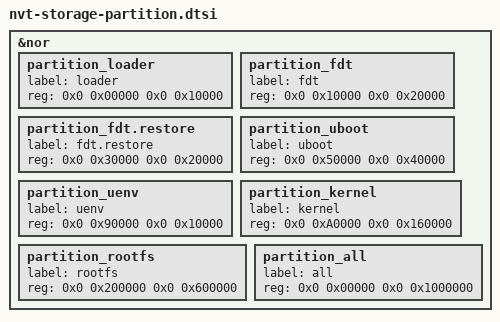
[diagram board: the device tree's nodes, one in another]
/*
 * Novatek Ltd. NA51055 BSP part of dts
 *
 * Cortex-A9
 *
 */

&nor {
	partition_loader {      label = "loader";       reg = <0x0 0x00000   0x0 0x10000>; }; /* Fixed */
	partition_fdt {	        label = "fdt";	        reg = <0x0 0x10000   0x0 0x20000>; }; /* Fixed */
	partition_fdt.restore {	label = "fdt.restore";	reg = <0x0 0x30000   0x0 0x20000>; }; /* Fixed */
	partition_uboot {       label = "uboot";        reg = <0x0 0x50000   0x0 0x40000>; };
	partition_uenv {        label = "uenv";         reg = <0x0 0x90000   0x0 0x10000>; };
	partition_kernel {      label = "kernel";       reg = <0x0 0xA0000   0x0 0x160000>; };
	partition_rootfs {      label = "rootfs";       reg = <0x0 0x200000  0x0 0x600000>; };
	partition_all {         label = "all";          reg = <0x0 0x00000   0x0 0x1000000>; };
};
